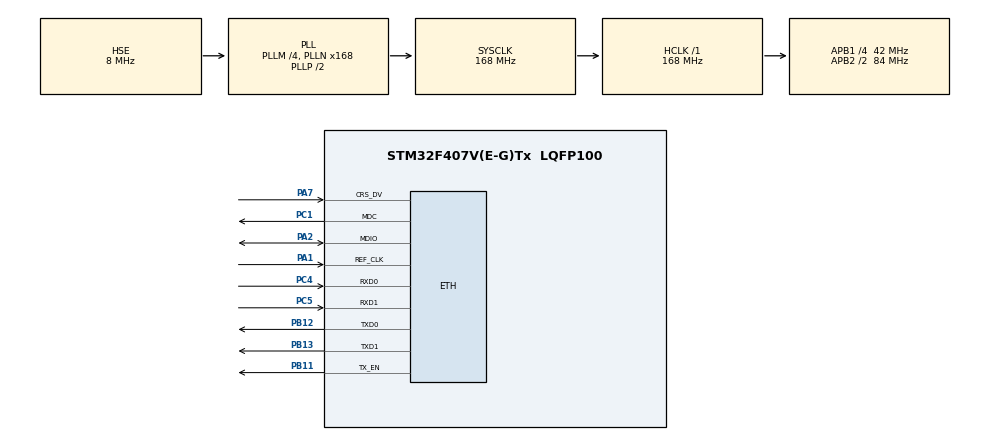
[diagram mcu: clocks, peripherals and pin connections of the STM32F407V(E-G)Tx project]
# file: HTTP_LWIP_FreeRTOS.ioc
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ETH.MediaInterface=ETH_MEDIA_INTERFACE_RMII
FREERTOS.Tasks01=defaultTask,24,500,StartDefaultTask,Default,NULL,Static,defaultTaskBuffer,defaultTaskControlBlock
FREERTOS.configUSE_NEWLIB_REENTRANT=1
LWIP.GATEWAY_ADDRESS=192.168.018.001
LWIP.IP_ADDRESS=192.168.018.123
LWIP.LWIP_DHCP=0
LWIP.NETMASK_ADDRESS=255.255.255.000
LWIP.Version=v2.1.2_Cube
Mcu.Family=STM32F4
Mcu.Name=STM32F407V(E-G)Tx
Mcu.Package=LQFP100
NVIC.ETH_IRQn=true\:5\:0\:false\:false\:true\:true\:false\:true
NVIC.PriorityGroup=NVIC_PRIORITYGROUP_4
NVIC.TIM8_TRG_COM_TIM14_IRQn=true\:15\:0\:false\:false\:true\:false\:false\:true
NVIC.TimeBase=TIM8_TRG_COM_TIM14_IRQn
NVIC.TimeBaseIP=TIM14
PA1.Mode=RMII
PA1.Signal=ETH_REF_CLK
PA13.Mode=Serial_Wire
PA13.Signal=SYS_JTMS-SWDIO
PA14.Mode=Serial_Wire
PA14.Signal=SYS_JTCK-SWCLK
PA2.Mode=RMII
PA2.Signal=ETH_MDIO
PA7.Mode=RMII
PA7.Signal=ETH_CRS_DV
PB11.Mode=RMII
PB11.Signal=ETH_TX_EN
PB12.Mode=RMII
PB12.Signal=ETH_TXD0
PB13.Mode=RMII
PB13.Signal=ETH_TXD1
PC1.Mode=RMII
PC1.Signal=ETH_MDC
PC4.Mode=RMII
PC4.Signal=ETH_RXD0
PC5.Mode=RMII
PC5.Signal=ETH_RXD1
PH0-OSC_IN.Mode=HSE-External-Oscillator
PH0-OSC_IN.Signal=RCC_OSC_IN
PH1-OSC_OUT.Mode=HSE-External-Oscillator
PH1-OSC_OUT.Signal=RCC_OSC_OUT
ProjectManager.HeapSize=0x200
ProjectManager.StackSize=0x400
ProjectManager.TargetToolchain=STM32CubeIDE
RCC.48MHZClocksFreq_Value=84000000
RCC.AHBFreq_Value=168000000
RCC.APB1CLKDivider=RCC_HCLK_DIV4
RCC.APB1Freq_Value=42000000
RCC.APB1TimFreq_Value=84000000
RCC.APB2CLKDivider=RCC_HCLK_DIV2
RCC.APB2Freq_Value=84000000
RCC.APB2TimFreq_Value=168000000
RCC.CortexFreq_Value=168000000
RCC.HCLKFreq_Value=168000000
RCC.HSE_VALUE=8000000
RCC.HSI_VALUE=16000000
RCC.LSE_VALUE=32768
RCC.PLLM=4
RCC.PLLN=168
RCC.PLLSourceVirtual=RCC_PLLSOURCE_HSE
RCC.SYSCLKFreq_VALUE=168000000
RCC.SYSCLKSource=RCC_SYSCLKSOURCE_PLLCLK
RCC.VCOOutputFreq_Value=336000000
VP_FREERTOS_VS_CMSIS_V2.Mode=CMSIS_V2
VP_LWIP_VS_Enabled.Mode=Enabled
VP_SYS_VS_tim14.Mode=TIM14
board=custom

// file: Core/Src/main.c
/* USER CODE BEGIN Header */
/**
  ******************************************************************************
  * @file           : main.c
  * @brief          : Main program body
  ******************************************************************************
  * @attention
  *
  * Copyright (c) 2022 STMicroelectronics.
  * All rights reserved.
  *
  * This software is licensed under terms that can be found in the LICENSE file
  * in the root directory of this software component.
  * If no LICENSE file comes with this software, it is provided AS-IS.
  *
  ******************************************************************************
  */
/* USER CODE END Header */
#include "main.h"
#include "cmsis_os.h"
#include "lwip.h"

/* USER CODE BEGIN Includes */
#include "httpserver-netconn.h"
/* USER CODE END Includes */

typedef StaticTask_t osStaticThreadDef_t;

/* Definitions for defaultTask */
osThreadId_t defaultTaskHandle;
uint32_t defaultTaskBuffer[ 500 ];
osStaticThreadDef_t defaultTaskControlBlock;
const osThreadAttr_t defaultTask_attributes = {
  .name = "defaultTask",
  .cb_mem = &defaultTaskControlBlock,
  .cb_size = sizeof(defaultTaskControlBlock),
  .stack_mem = &defaultTaskBuffer[0],
  .stack_size = sizeof(defaultTaskBuffer),
  .priority = (osPriority_t) osPriorityNormal,
};

void SystemClock_Config(void);
static void MX_GPIO_Init(void);
void StartDefaultTask(void *argument);

int main(void)
{

  /* MCU Configuration--------------------------------------------------------*/

  /* Reset of all peripherals, Initializes the Flash interface and the Systick. */
  HAL_Init();

  /* Configure the system clock */
  SystemClock_Config();

  /* Initialize all configured peripherals */
  MX_GPIO_Init();

  /* Init scheduler */
  osKernelInitialize();

  /* Create the thread(s) */
  /* creation of defaultTask */
  defaultTaskHandle = osThreadNew(StartDefaultTask, NULL, &defaultTask_attributes);

  /* Start scheduler */
  osKernelStart();

  /* We should never get here as control is now taken by the scheduler */
  /* Infinite loop */
  while (1)
  {

  }
}

void SystemClock_Config(void)
{
  RCC_OscInitTypeDef RCC_OscInitStruct = {0};
  RCC_ClkInitTypeDef RCC_ClkInitStruct = {0};

  /** Configure the main internal regulator output voltage
  */
  __HAL_RCC_PWR_CLK_ENABLE();
  __HAL_PWR_VOLTAGESCALING_CONFIG(PWR_REGULATOR_VOLTAGE_SCALE1);
  /** Initializes the RCC Oscillators according to the specified parameters
  * in the RCC_OscInitTypeDef structure.
  */
  RCC_OscInitStruct.OscillatorType = RCC_OSCILLATORTYPE_HSE;
  RCC_OscInitStruct.HSEState = RCC_HSE_ON;
  RCC_OscInitStruct.PLL.PLLState = RCC_PLL_ON;
  RCC_OscInitStruct.PLL.PLLSource = RCC_PLLSOURCE_HSE;
  RCC_OscInitStruct.PLL.PLLM = 4;
  RCC_OscInitStruct.PLL.PLLN = 168;
  RCC_OscInitStruct.PLL.PLLP = RCC_PLLP_DIV2;
  RCC_OscInitStruct.PLL.PLLQ = 4;
  if (HAL_RCC_OscConfig(&RCC_OscInitStruct) != HAL_OK)
  {
    Error_Handler();
  }
  /** Initializes the CPU, AHB and APB buses clocks
  */
  RCC_ClkInitStruct.ClockType = RCC_CLOCKTYPE_HCLK|RCC_CLOCKTYPE_SYSCLK
                              |RCC_CLOCKTYPE_PCLK1|RCC_CLOCKTYPE_PCLK2;
  RCC_ClkInitStruct.SYSCLKSource = RCC_SYSCLKSOURCE_PLLCLK;
  RCC_ClkInitStruct.AHBCLKDivider = RCC_SYSCLK_DIV1;
  RCC_ClkInitStruct.APB1CLKDivider = RCC_HCLK_DIV4;
  RCC_ClkInitStruct.APB2CLKDivider = RCC_HCLK_DIV2;

  if (HAL_RCC_ClockConfig(&RCC_ClkInitStruct, FLASH_LATENCY_5) != HAL_OK)
  {
    Error_Handler();
  }
}

static void MX_GPIO_Init(void)
{

  /* GPIO Ports Clock Enable */
  __HAL_RCC_GPIOH_CLK_ENABLE();
  __HAL_RCC_GPIOC_CLK_ENABLE();
  __HAL_RCC_GPIOA_CLK_ENABLE();
  __HAL_RCC_GPIOB_CLK_ENABLE();

}

void StartDefaultTask(void *argument)
{
  /* init code for LWIP */
  MX_LWIP_Init();
  /* USER CODE BEGIN 5 */
  http_server_netconn_init();
  /* Infinite loop */
  for(;;)
  {
    osDelay(1);
  }
  /* USER CODE END 5 */
}

void HAL_TIM_PeriodElapsedCallback(TIM_HandleTypeDef *htim)
{
  if (htim->Instance == TIM14) {
    HAL_IncTick();
  }
}

void Error_Handler(void)
{
  __disable_irq();
  while (1)
  {
  }
}
